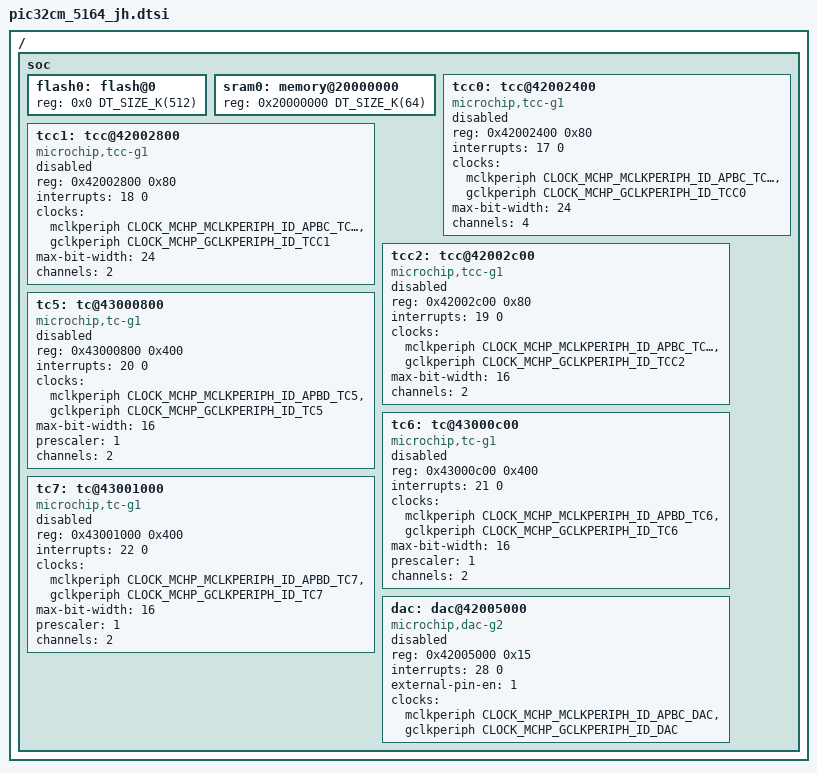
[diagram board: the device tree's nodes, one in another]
/*
 * Copyright (c) 2025-2026 Microchip Technology Inc.
 *
 * SPDX-License-Identifier: Apache-2.0
 */

/*
 * Memory configuration: Flash size, RAM Size, Data Flash size
 * and additional nodes for 5164 memory variants
 */
#include <zephyr/dt-bindings/pwm/pwm.h>

/ {
	soc {
		flash0: flash@0 {
			reg = <0x0 DT_SIZE_K(512)>;
		};

		sram0: memory@20000000 {
			reg = <0x20000000 DT_SIZE_K(64)>;
		};

		tcc0: tcc@42002400 {
			compatible = "microchip,tcc-g1";
			reg = <0x42002400 0x80>;
			interrupts = <17 0>;
			interrupt-names = "mc3-mc0";
			clocks = <&mclkperiph CLOCK_MCHP_MCLKPERIPH_ID_APBC_TCC0>,
				 <&gclkperiph CLOCK_MCHP_GCLKPERIPH_ID_TCC0>;
			clock-names = "mclk", "gclk";
			max-bit-width = <24>;
			channels = <4>;
			status = "disabled";
		};

		tcc1: tcc@42002800 {
			compatible = "microchip,tcc-g1";
			reg = <0x42002800 0x80>;
			interrupts = <18 0>;
			interrupt-names = "mc3-mc0";
			clocks = <&mclkperiph CLOCK_MCHP_MCLKPERIPH_ID_APBC_TCC1>,
				 <&gclkperiph CLOCK_MCHP_GCLKPERIPH_ID_TCC1>;
			clock-names = "mclk", "gclk";
			max-bit-width = <24>;
			channels = <2>;
			status = "disabled";
		};

		tcc2: tcc@42002c00 {
			compatible = "microchip,tcc-g1";
			reg = <0x42002c00 0x80>;
			interrupts = <19 0>;
			interrupt-names = "mc3-mc0";
			clocks = <&mclkperiph CLOCK_MCHP_MCLKPERIPH_ID_APBC_TCC2>,
				 <&gclkperiph CLOCK_MCHP_GCLKPERIPH_ID_TCC2>;
			clock-names = "mclk", "gclk";
			max-bit-width = <16>;
			channels = <2>;
			status = "disabled";
		};

		tc5: tc@43000800 {
			compatible = "microchip,tc-g1";
			reg = <0x43000800 0x400>;
			interrupts = <20 0>;
			interrupt-names = "mc0-1";
			clocks = <&mclkperiph CLOCK_MCHP_MCLKPERIPH_ID_APBD_TC5>,
				 <&gclkperiph CLOCK_MCHP_GCLKPERIPH_ID_TC5>;
			clock-names = "mclk", "gclk";
			max-bit-width = <16>;
			prescaler = <1>;
			channels = <2>;
			status = "disabled";
		};

		tc6: tc@43000c00 {
			compatible = "microchip,tc-g1";
			reg = <0x43000c00 0x400>;
			interrupts = <21 0>;
			interrupt-names = "mc0-1";
			clocks = <&mclkperiph CLOCK_MCHP_MCLKPERIPH_ID_APBD_TC6>,
				 <&gclkperiph CLOCK_MCHP_GCLKPERIPH_ID_TC6>;
			clock-names = "mclk", "gclk";
			max-bit-width = <16>;
			prescaler = <1>;
			channels = <2>;
			status = "disabled";
		};

		tc7: tc@43001000 {
			compatible = "microchip,tc-g1";
			reg = <0x43001000 0x400>;
			interrupts = <22 0>;
			interrupt-names = "mc0-1";
			clocks = <&mclkperiph CLOCK_MCHP_MCLKPERIPH_ID_APBD_TC7>,
				 <&gclkperiph CLOCK_MCHP_GCLKPERIPH_ID_TC7>;
			clock-names = "mclk", "gclk";
			max-bit-width = <16>;
			prescaler = <1>;
			channels = <2>;
			status = "disabled";
		};

		dac: dac@42005000 {
			compatible = "microchip,dac-g2";
			reg = <0x42005000 0x15>;
			interrupts = <28 0>;
			interrupt-names = "source-0-1";
			#io-channel-cells = <1>;
			external-pin-en = <1>;
			clocks = <&mclkperiph CLOCK_MCHP_MCLKPERIPH_ID_APBC_DAC>,
				 <&gclkperiph CLOCK_MCHP_GCLKPERIPH_ID_DAC>;
			clock-names = "mclk", "gclk";
			status = "disabled";
		};
	};
};
